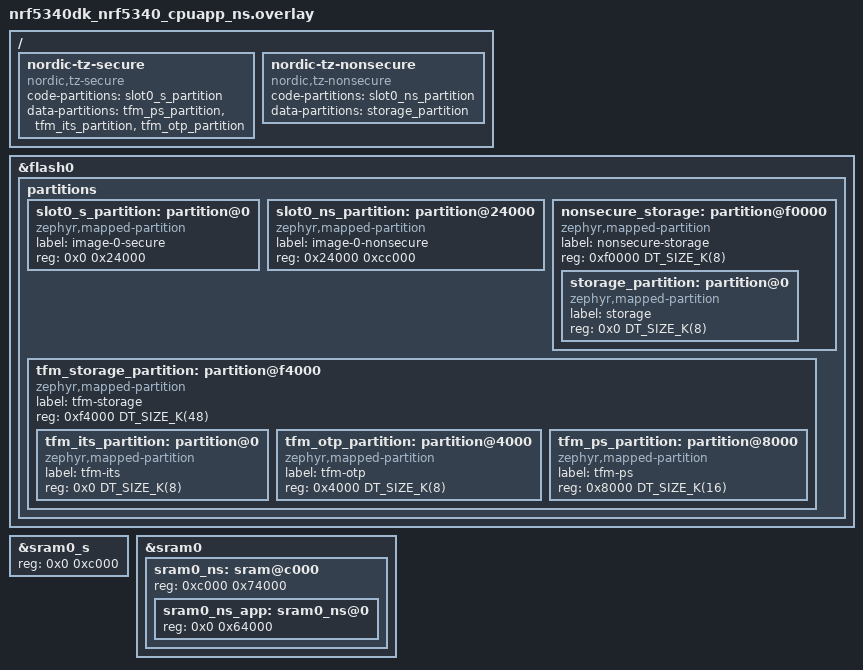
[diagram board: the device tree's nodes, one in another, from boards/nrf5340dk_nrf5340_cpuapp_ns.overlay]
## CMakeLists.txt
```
#
# Copyright (c) 2024 Nordic Semiconductor ASA
#
# SPDX-License-Identifier: LicenseRef-Nordic-5-Clause
#

cmake_minimum_required(VERSION 3.20.0)

find_package(Zephyr REQUIRED HINTS $ENV{ZEPHYR_BASE})
project(softap_wifi_provision_sample)

target_sources(app PRIVATE src/main.c)
```

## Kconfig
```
#
# Copyright (c) 2024 Nordic Semiconductor ASA
#
# SPDX-License-Identifier: LicenseRef-Nordic-5-Clause
#

menu "SoftAP Wi-Fi provision sample"

config SOFTAP_WIFI_PROVISION_SAMPLE_PSM_DISABLED_SECONDS
	int "Wi-Fi PSM disabled seconds"
	default 120
	help
	  Time in seconds that Wi-Fi power saving mode is disabled after completed provisioning.
	  Disabling Power Save Mode is needed to make the device discoverable reliably via
	  mDNS post provisioning.
	  Service Discovery has proven to be unstable in PSM.

menu "Zephyr Kernel"
source "Kconfig.zephyr"
endmenu

module = SOFTAP_WIFI_PROVISION_SAMPLE
module-str = SoftAP Wi-Fi provision sample
source "$(ZEPHYR_BASE)/subsys/logging/Kconfig.template.log_config"

endmenu
```

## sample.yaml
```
sample:
  name: SoftAP Wi-Fi Provision sample
tests:
  sample.softap.wifi.provision:
    sysbuild: true
    build_only: true
    platform_allow: nrf7002dk/nrf5340/cpuapp/ns
    integration_platforms:
      - nrf7002dk/nrf5340/cpuapp/ns
    tags:
      - ci_build
      - sysbuild
      - ci_samples_wifi
  sample.nrf7002_eks.softap.wifi.provision:
    sysbuild: true
    build_only: true
    extra_args:
      - softap_SHIELD=nrf7002ek
    integration_platforms:
      - nrf5340dk/nrf5340/cpuapp/ns
    platform_allow:
      - nrf5340dk/nrf5340/cpuapp/ns
    tags:
      - ci_build
      - sysbuild
      - ci_samples_wifi
  sample.nrf54l15.softap.wifi.provision:
    sysbuild: true
    build_only: true
    extra_args:
      - softap_SHIELD="nrf7002eb_interposer_p1;nrf7002eb"
      - softap_SNIPPET=nrf70-wifi
      - CONFIG_HEAP_MEM_POOL_IGNORE_MIN=n
    integration_platforms:
      - nrf54l15dk/nrf54l15/cpuapp
    platform_allow:
      - nrf54l15dk/nrf54l15/cpuapp
    tags:
      - ci_build
      - sysbuild
      - ci_samples_wifi
  sample.nrf54h20.nrf7002eb_interposer_p1.softap.wifi.provision:
    sysbuild: true
    build_only: true
    extra_args:
      - softap_SHIELD="nrf7002eb_interposer_p1;nrf7002eb"
      - softap_SNIPPET=nrf70-wifi
      - CONFIG_MBEDTLS_SSL_SERVER_NAME_INDICATION=n
    integration_platforms:
      - nrf54h20dk/nrf54h20/cpuapp
    platform_allow:
      - nrf54h20dk/nrf54h20/cpuapp
    tags:
      - ci_build
      - sysbuild
      - ci_samples_wifi
  sample.54lm20dk.nrf7002eb2.softap.wifi.provision:
    sysbuild: true
    build_only: true
    extra_args:
      - softap_SHIELD="nrf7002eb2"
    integration_platforms:
      - nrf54lm20dk/nrf54lm20a/cpuapp
      - nrf54lm20dk/nrf54lm20b/cpuapp
    platform_allow:
      - nrf54lm20dk/nrf54lm20a/cpuapp
      - nrf54lm20dk/nrf54lm20b/cpuapp
    tags:
      - ci_build
      - sysbuild
      - ci_samples_wifi
  sample.nrf7120.softap.wifi.provision:
    sysbuild: true
    build_only: true
    integration_platforms:
      - nrf7120dk/nrf7120/cpuapp/ns
    platform_allow:
      - nrf7120dk/nrf7120/cpuapp/ns
      - nrf7120dk/nrf7120e/cpuapp/ns
    tags:
      - ci_build
      - sysbuild
      - ci_samples_nrf71_wifi
```

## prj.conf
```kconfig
#
# Copyright (c) 2024 Nordic Semiconductor ASA
#
# SPDX-License-Identifier: LicenseRef-Nordic-5-Clause
#

# Optimize TF-M
CONFIG_TFM_PROFILE_TYPE_SMALL=y

# Optimize Wi-Fi stack to save some memory.
CONFIG_NRF_WIFI_DATA_HEAP_SIZE=53000

# Wi-Fi
CONFIG_WIFI=y
CONFIG_WIFI_NM_WPA_SUPPLICANT=y
CONFIG_WIFI_NM_WPA_SUPPLICANT_AP=y
CONFIG_NET_L2_ETHERNET=y
CONFIG_WIFI_CREDENTIALS=y
CONFIG_SETTINGS=y

# General
CONFIG_LOG=y
CONFIG_LOG_MODE_IMMEDIATE=y
CONFIG_ASSERT=y
CONFIG_ASSERT_VERBOSE=n
CONFIG_REBOOT=y

# Link-time optimizations
CONFIG_LTO=y
CONFIG_ISR_TABLES_LOCAL_DECLARATION=y

# Temporarily enable FS support so that linking succeeds.
CONFIG_FILE_SYSTEM=y
CONFIG_MAIN_STACK_SIZE=6704
CONFIG_NANOPB=y
CONFIG_SMF=y

# Scan Results
CONFIG_SOFTAP_WIFI_PROVISION_SAMPLE_SCAN_RESULTS=20

# HTTP parser
CONFIG_HTTP_PARSER=y
CONFIG_HTTP_PARSER_URL=y

# DK Butons and LEDs
CONFIG_DK_LIBRARY=y

# Networking config
CONFIG_NETWORKING=y
CONFIG_NET_CONNECTION_MANAGER=y
CONFIG_NET_IPV4=y
# Disable IPv6 to save memory
CONFIG_NET_IPV6=n
CONFIG_NET_TCP=y
CONFIG_NET_UDP=y
CONFIG_NET_SOCKETS=y
CONFIG_NET_MAX_CONN=8
CONFIG_NET_SOCKETS_TLS_MAX_CONTEXTS=2
CONFIG_NET_SOCKETS_SOCKOPT_TLS=y

# Zephyr NET Connection Manager connectivity layer
CONFIG_L2_WIFI_CONNECTIVITY=y
CONFIG_L2_WIFI_CONNECTIVITY_AUTO_CONNECT=n
CONFIG_L2_WIFI_CONNECTIVITY_AUTO_DOWN=n

# SoftAP Wi-Fi Provision library
CONFIG_SOFTAP_WIFI_PROVISION=y
CONFIG_SOFTAP_WIFI_PROVISION_THREAD_STACK_SIZE=8192
# Disable socket close on completed provisioning to keep mDNS SD running.
# SD depends on the socket being open for a specified port.
CONFIG_SOFTAP_WIFI_PROVISION_SOCKET_CLOSE_ON_COMPLETION=n
CONFIG_SOFTAP_WIFI_PROVISION_LOG_LEVEL_DBG=y
CONFIG_WIFI_NM_WPA_SUPPLICANT_THREAD_STACK_SIZE=8192

# (M)DNS
CONFIG_MDNS_RESPONDER=y
CONFIG_DNS_SD=y
CONFIG_MDNS_RESPONDER_DNS_SD=y
CONFIG_NET_HOSTNAME_ENABLE=y
CONFIG_NET_HOSTNAME="wifiprov"
# Disable POSIX uname support to suppress build warning that hostname is too long.
CONFIG_POSIX_SINGLE_PROCESS=n

# DHCPv4 client and server
CONFIG_NET_DHCPV4=y
CONFIG_NET_DHCPV4_SERVER=y

# Store TLS credentials to protected storage.
CONFIG_TLS_CREDENTIALS=y
CONFIG_TLS_CREDENTIALS_BACKEND_PROTECTED_STORAGE=y

CONFIG_FLASH=y
CONFIG_FLASH_PAGE_LAYOUT=y
CONFIG_FLASH_MAP=y
CONFIG_ZMS=y
CONFIG_SETTINGS=y
CONFIG_SETTINGS_ZMS=y

# Disable auto init of NET config as the softAP Wi-Fi provision library will manually set its
# own IP configuration.
CONFIG_NET_CONFIG_AUTO_INIT=n

# Default mbedTLS heap is 512 B; PEM decode of server cert/key needs more or load fails with
# MBEDTLS_ERR_PEM_ALLOC_FAILED (-0x1180) during tls_credential_add().
CONFIG_MBEDTLS_HEAP_SIZE=49152

# nrf_security can leave PEM parsing off; embedded PEM certs need this or x509 parse fails with
# MBEDTLS_ERR_X509_INVALID_FORMAT (-0x2180).
CONFIG_MBEDTLS_PEM_PARSE_C=y

# Embedded PEMs are ECDSA P-256 (prime256v1). PSA must list
# secp256r1 and ECDSA/ECDH or mbedtls_x509_crt_parse() returns MBEDTLS_ERR_X509_INVALID_FORMAT
# (-0x2180). TLS server ECDHE uses psa_generate_key() then psa_export_public_key() for the
# ephemeral key; without PSA_WANT_KEY_TYPE_ECC_KEY_PAIR_GENERATE / EXPORT, those calls map to
# MBEDTLS_ERR_SSL_FEATURE_UNAVAILABLE (-0x7080). See samples/crypto/psa_tls/prj.conf.
CONFIG_PSA_WANT_ALG_ECDSA=y
CONFIG_PSA_WANT_ALG_ECDH=y
CONFIG_PSA_WANT_ECC_SECP_R1_256=y
CONFIG_PSA_WANT_KEY_TYPE_ECC_PUBLIC_KEY=y
CONFIG_PSA_WANT_KEY_TYPE_ECC_KEY_PAIR_IMPORT=y
CONFIG_PSA_WANT_KEY_TYPE_ECC_KEY_PAIR_GENERATE=y
CONFIG_PSA_WANT_KEY_TYPE_ECC_KEY_PAIR_EXPORT=y
```

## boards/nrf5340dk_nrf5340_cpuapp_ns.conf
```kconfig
#
# Copyright (c) 2026 Nordic Semiconductor ASA
#
# SPDX-License-Identifier: LicenseRef-Nordic-5-Clause
#

# Store Wi-Fi credentials using PSA storage
CONFIG_TFM_PROFILE_TYPE_SMALL=y
CONFIG_MBEDTLS_PSA_CRYPTO_C=y

# Some size optimizations to accommodate non-secure builds.
CONFIG_NET_STATISTICS=n
CONFIG_NET_STATISTICS_WIFI=n
CONFIG_NET_STATISTICS_USER_API=n
CONFIG_NET_PKT_RX_COUNT=8
CONFIG_NET_PKT_TX_COUNT=4
CONFIG_NET_BUF_RX_COUNT=8
CONFIG_NET_BUF_TX_COUNT=8
CONFIG_NET_TC_TX_COUNT=1
CONFIG_NET_TX_STACK_SIZE=2048
CONFIG_NET_RX_STACK_SIZE=2048
```

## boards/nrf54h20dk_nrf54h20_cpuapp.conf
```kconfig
CONFIG_WIFI_CREDENTIALS=y
# Needed for Wi-Fi credentials
CONFIG_FLASH=y
CONFIG_FLASH_PAGE_LAYOUT=y
CONFIG_FLASH_MAP=y
CONFIG_ZMS=y
CONFIG_SETTINGS=y
```

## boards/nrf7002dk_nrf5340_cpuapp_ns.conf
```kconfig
#
# Copyright (c) 2026 Nordic Semiconductor ASA
#
# SPDX-License-Identifier: LicenseRef-Nordic-5-Clause
#

# Store Wi-Fi credentials using PSA storage
CONFIG_TFM_PROFILE_TYPE_SMALL=y
CONFIG_MBEDTLS_PSA_CRYPTO_C=y

# Some size optimizations to accommodate non-secure builds.
CONFIG_NET_STATISTICS=n
CONFIG_NET_STATISTICS_WIFI=n
CONFIG_NET_STATISTICS_USER_API=n
CONFIG_NET_PKT_RX_COUNT=8
CONFIG_NET_PKT_TX_COUNT=4
CONFIG_NET_BUF_RX_COUNT=8
CONFIG_NET_BUF_TX_COUNT=8
CONFIG_NET_TC_TX_COUNT=1
CONFIG_NET_TX_STACK_SIZE=2048
CONFIG_NET_RX_STACK_SIZE=2048

#NRF70 specific configuration
CONFIG_WIFI_NRF70=y
CONFIG_NRF70_AP_MODE=y
CONFIG_NRF_WIFI_DATA_HEAP_SIZE=53000
```

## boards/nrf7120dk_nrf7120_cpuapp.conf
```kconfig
#
# Copyright (c) 2026 Nordic Semiconductor
#
# SPDX-License-Identifier: LicenseRef-Nordic-5-Clause
#

CONFIG_WIFI_NRF71=y
CONFIG_NRF71_AP_MODE=y
CONFIG_NRF71_RX_NUM_BUFS=16
CONFIG_NRF71_MAX_TX_AGGREGATION=4
CONFIG_NRF_WIFI_DATA_HEAP_SIZE=90000
```

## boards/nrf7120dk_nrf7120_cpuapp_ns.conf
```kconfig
#
# Copyright (c) 2026 Nordic Semiconductor
#
# SPDX-License-Identifier: LicenseRef-Nordic-5-Clause
#

CONFIG_WIFI_NRF71=y
CONFIG_NRF71_WIFI_AP_SUPPORT=y
CONFIG_NRF71_WIFI_RX_NUM_BUFS=16
CONFIG_NRF71_WIFI_MAX_TX_AGGREGATION=4
CONFIG_NRF71_WIFI_DATA_HEAP_SIZE=90000

# nRF7120 (SOC_SERIES_NRF71) defaults TFM_ITS_ENCRYPTED=y, which conflicts with
# PSA_FRAMEWORK_HAS_MM_IOVEC (enabled via TFM_PROFILE_TYPE_SMALL in prj.conf).
# TLS credentials use PS (Protected Storage), not ITS, so disabling ITS encryption
# is safe here.
CONFIG_TFM_ITS_ENCRYPTED=n

CONFIG_DK_LIBRARY=n
```

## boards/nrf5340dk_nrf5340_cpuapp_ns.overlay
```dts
/*
 * Copyright (c) 2026 Nordic Semiconductor ASA
 *
 * SPDX-License-Identifier: LicenseRef-Nordic-5-Clause
 */

/*
 * Flash partition layout for nRF5340DK (nRF5340 cpuapp/ns) without MCUboot.
 * PM is disabled; TF-M is the only S-mode component.
 *
 *   slot0_s_partition  @ 0x000000  144 KB  TF-M secure image
 *   slot0_ns_partition @ 0x024000  816 KB  NS application image
 *   nonsecure_storage  @ 0x0f0000    8 KB  Settings (NS-accessible)
 *   tfm_storage        @ 0x0f4000   48 KB  TF-M ITS + OTP + PS
 */

/delete-node/ &boot_partition;
/delete-node/ &slot0_partition;
/delete-node/ &slot1_partition;
/delete-node/ &tfm_its_partition;
/delete-node/ &tfm_otp_partition;
/delete-node/ &tfm_ps_partition;
/delete-node/ &storage_partition;
/delete-node/ &sram0_ns;

&flash0 {
	partitions {
		slot0_s_partition: partition@0 {
			compatible = "zephyr,mapped-partition";
			label = "image-0-secure";
			reg = <0x0 0x24000>;
		};

		slot0_ns_partition: partition@24000 {
			compatible = "zephyr,mapped-partition";
			label = "image-0-nonsecure";
			reg = <0x24000 0xcc000>;
		};

		nonsecure_storage: partition@f0000 {
			compatible = "zephyr,mapped-partition";
			label = "nonsecure-storage";
			reg = <0xf0000 DT_SIZE_K(8)>;
			ranges = <0x0 0xf0000 DT_SIZE_K(8)>;
			#address-cells = <1>;
			#size-cells = <1>;

			storage_partition: partition@0 {
				compatible = "zephyr,mapped-partition";
				label = "storage";
				reg = <0x0 DT_SIZE_K(8)>;
			};
		};

		tfm_storage_partition: partition@f4000 {
			compatible = "zephyr,mapped-partition";
			label = "tfm-storage";
			reg = <0xf4000 DT_SIZE_K(48)>;
			ranges = <0x0 0xf4000 DT_SIZE_K(48)>;
			#address-cells = <1>;
			#size-cells = <1>;

			tfm_its_partition: partition@0 {
				compatible = "zephyr,mapped-partition";
				label = "tfm-its";
				reg = <0x0 DT_SIZE_K(8)>;
			};

			tfm_otp_partition: partition@4000 {
				compatible = "zephyr,mapped-partition";
				label = "tfm-otp";
				reg = <0x4000 DT_SIZE_K(8)>;
			};

			tfm_ps_partition: partition@8000 {
				compatible = "zephyr,mapped-partition";
				label = "tfm-ps";
				reg = <0x8000 DT_SIZE_K(16)>;
			};
		};
	};
};

/*
 * SRAM split: TF-M secure uses 48 KiB at base; NS app gets the rest.
 */
&sram0_s {
	reg = <0x0 0xc000>;
};

&sram0 {
	sram0_ns: sram@c000 {
		#address-cells = <1>;
		#size-cells = <1>;
		reg = <0xc000 0x74000>;
		ranges = <0x0 0xc000 0x74000>;

		sram0_ns_app: sram0_ns@0 {
			reg = <0x0 0x64000>;
		};
	};
};

/ {
	/delete-node/ nordic-tz-secure;
	/delete-node/ nordic-tz-nonsecure;

	nordic-tz-secure {
		compatible = "nordic,tz-secure";
		code-partitions = <&slot0_s_partition>;
		data-partitions = <&tfm_ps_partition>,
				  <&tfm_its_partition>,
				  <&tfm_otp_partition>;
	};

	nordic-tz-nonsecure {
		compatible = "nordic,tz-nonsecure";
		code-partitions = <&slot0_ns_partition>;
		data-partitions = <&storage_partition>;
	};
};
```

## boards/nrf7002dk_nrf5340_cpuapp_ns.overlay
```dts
/*
 * Copyright (c) 2026 Nordic Semiconductor ASA
 *
 * SPDX-License-Identifier: LicenseRef-Nordic-5-Clause
 */

/*
 * Flash partition layout for nRF7002DK (nRF5340 cpuapp/ns) without MCUboot.
 * PM is disabled; TF-M is the only S-mode component.
 *
 *   slot0_s_partition  @ 0x000000  144 KB  TF-M secure image
 *   slot0_ns_partition @ 0x024000  816 KB  NS application image
 *   nonsecure_storage  @ 0x0f0000    8 KB  Settings (NS-accessible)
 *   tfm_storage        @ 0x0f4000   48 KB  TF-M ITS + OTP + PS
 */

/delete-node/ &boot_partition;
/delete-node/ &slot0_partition;
/delete-node/ &slot1_partition;
/delete-node/ &tfm_its_partition;
/delete-node/ &tfm_otp_partition;
/delete-node/ &tfm_ps_partition;
/delete-node/ &storage_partition;
/delete-node/ &sram0_ns;

&flash0 {
	partitions {
		slot0_s_partition: partition@0 {
			compatible = "zephyr,mapped-partition";
			label = "image-0-secure";
			reg = <0x0 0x24000>;
		};

		slot0_ns_partition: partition@24000 {
			compatible = "zephyr,mapped-partition";
			label = "image-0-nonsecure";
			reg = <0x24000 0xcc000>;
		};

		nonsecure_storage: partition@f0000 {
			compatible = "zephyr,mapped-partition";
			label = "nonsecure-storage";
			reg = <0xf0000 DT_SIZE_K(8)>;
			ranges = <0x0 0xf0000 DT_SIZE_K(8)>;
			#address-cells = <1>;
			#size-cells = <1>;

			storage_partition: partition@0 {
				compatible = "zephyr,mapped-partition";
				label = "storage";
				reg = <0x0 DT_SIZE_K(8)>;
			};
		};

		tfm_storage_partition: partition@f4000 {
			compatible = "zephyr,mapped-partition";
			label = "tfm-storage";
			reg = <0xf4000 DT_SIZE_K(48)>;
			ranges = <0x0 0xf4000 DT_SIZE_K(48)>;
			#address-cells = <1>;
			#size-cells = <1>;

			tfm_its_partition: partition@0 {
				compatible = "zephyr,mapped-partition";
				label = "tfm-its";
				reg = <0x0 DT_SIZE_K(8)>;
			};

			tfm_otp_partition: partition@4000 {
				compatible = "zephyr,mapped-partition";
				label = "tfm-otp";
				reg = <0x4000 DT_SIZE_K(8)>;
			};

			tfm_ps_partition: partition@8000 {
				compatible = "zephyr,mapped-partition";
				label = "tfm-ps";
				reg = <0x8000 DT_SIZE_K(16)>;
			};
		};
	};
};

/*
 * SRAM split: TF-M secure uses 48 KiB at base; NS app gets the rest.
 */
&sram0_s {
	reg = <0x0 0xc000>;
};

&sram0 {
	sram0_ns: sram@c000 {
		#address-cells = <1>;
		#size-cells = <1>;
		reg = <0xc000 0x74000>;
		ranges = <0x0 0xc000 0x74000>;

		sram0_ns_app: sram0_ns@0 {
			reg = <0x0 0x64000>;
		};
	};
};

/ {
	/delete-node/ nordic-tz-secure;
	/delete-node/ nordic-tz-nonsecure;

	nordic-tz-secure {
		compatible = "nordic,tz-secure";
		code-partitions = <&slot0_s_partition>;
		data-partitions = <&tfm_ps_partition>,
				  <&tfm_its_partition>,
				  <&tfm_otp_partition>;
	};

	nordic-tz-nonsecure {
		compatible = "nordic,tz-nonsecure";
		code-partitions = <&slot0_ns_partition>;
		data-partitions = <&storage_partition>;
	};
};
```

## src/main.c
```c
/*
 * Copyright (c) 2024 Nordic Semiconductor ASA
 *
 * SPDX-License-Identifier: LicenseRef-Nordic-5-Clause
 */

#include <stdio.h>
#include <errno.h>
#include <zephyr/kernel.h>
#include <zephyr/logging/log.h>
#include <zephyr/logging/log_ctrl.h>
#include <zephyr/sys/reboot.h>
#include <zephyr/net/wifi_mgmt.h>
#include <zephyr/net/net_mgmt.h>
#include <zephyr/net/net_event.h>
#include <zephyr/net/conn_mgr_monitor.h>
#include <zephyr/net/conn_mgr_connectivity.h>
#include <zephyr/net/dhcpv4.h>
#include <dk_buttons_and_leds.h>
#include <net/softap_wifi_provision.h>

LOG_MODULE_REGISTER(softap_wifi_provision_sample, CONFIG_SOFTAP_WIFI_PROVISION_SAMPLE_LOG_LEVEL);

/* Macro used to subscribe to specific Zephyr NET management events. */
#define L4_EVENT_MASK (NET_EVENT_L4_CONNECTED | NET_EVENT_L4_DISCONNECTED)
#define CONN_LAYER_EVENT_MASK (NET_EVENT_CONN_IF_FATAL_ERROR)

/* Macro called upon a fatal error, reboots the device. */
#define FATAL_ERROR()								\
	LOG_ERR("Fatal error!%s", IS_ENABLED(CONFIG_RESET_ON_FATAL_ERROR) ?	\
				  " Rebooting the device" : "");		\
	LOG_PANIC();								\
	IF_ENABLED(CONFIG_REBOOT, (sys_reboot(0)))

/* Callbacks for Zephyr NET management events. */
static struct net_mgmt_event_callback l4_cb;
static struct net_mgmt_event_callback conn_cb;

static void l4_event_handler(struct net_mgmt_event_callback *cb,
			     uint64_t event,
			     struct net_if *iface)
{
	switch (event) {
	case NET_EVENT_L4_CONNECTED:
		LOG_INF("Network connected");

#ifdef CONFIG_DK_LIBRARY
		int ret = dk_set_led_on(DK_LED2);

		if (ret) {
			LOG_ERR("dk_set_led_on, error: %d", ret);
			FATAL_ERROR();
			return;
		}
#endif /* CONFIG_DK_LIBRARY */

		/* Start the DHCPv4 client after the device is provisioned to a network.
		 * This is needed to get a dynamic IPv4 address from the APs DHCPv4 server.
		 */
		net_dhcpv4_start(iface);
		break;
	case NET_EVENT_L4_DISCONNECTED:
		LOG_INF("Network disconnected");
		break;
	default:
		/* Don't care */
		return;
	}
}

static void connectivity_event_handler(struct net_mgmt_event_callback *cb,
				       uint64_t event,
				       struct net_if *iface)
{
	if (event == NET_EVENT_CONN_IF_FATAL_ERROR) {
		LOG_ERR("NET_EVENT_CONN_IF_FATAL_ERROR");
		FATAL_ERROR();
		return;
	}
}

/* Callback for softAP Wi-Fi provision library events. */
static void softap_wifi_provision_handler(const struct softap_wifi_provision_evt *evt)
{
	switch (evt->type) {
	case SOFTAP_WIFI_PROVISION_EVT_STARTED:
		LOG_INF("Provisioning started");
#ifdef CONFIG_DK_LIBRARY
		int ret;

		ret = dk_set_led_on(DK_LED1);
		if (ret) {
			LOG_ERR("dk_set_led_on, error: %d", ret);
			FATAL_ERROR();
			return;
		}
#endif /* CONFIG_DK_LIBRARY */

		break;
	case SOFTAP_WIFI_PROVISION_EVT_CLIENT_CONNECTED:
		LOG_INF("Client connected");
		break;
	case SOFTAP_WIFI_PROVISION_EVT_CLIENT_DISCONNECTED:
		LOG_INF("Client disconnected");
		break;
	case SOFTAP_WIFI_PROVISION_EVT_CREDENTIALS_RECEIVED:
		LOG_INF("Wi-Fi credentials received");
		break;
	case SOFTAP_WIFI_PROVISION_EVT_COMPLETED:
		LOG_INF("Provisioning completed");
		break;
	case SOFTAP_WIFI_PROVISION_EVT_UNPROVISIONED_REBOOT_NEEDED:
		LOG_INF("Reboot request notified, rebooting...");

		LOG_PANIC();
		IF_ENABLED(CONFIG_REBOOT, (sys_reboot(0)));
		break;
	case SOFTAP_WIFI_PROVISION_EVT_FATAL_ERROR:
		LOG_ERR("Provisioning failed, fatal error!");
		FATAL_ERROR();
		break;
	default:
		/* Don't care */
		return;
	}
}

#ifdef CONFIG_DK_LIBRARY
static void button_handler(uint32_t button_states, uint32_t has_changed)
{
	if ((has_changed & DK_BTN1_MSK) && (button_states & DK_BTN1_MSK)) {
		LOG_INF("Button 1 pressed");

		int ret = softap_wifi_provision_reset();

		if (ret) {
			LOG_ERR("softap_wifi_provision_reset, error: %d", ret);
			FATAL_ERROR();
			return;
		}
	}
}
#endif /* CONFIG_DK_LIBRARY */

static int wifi_power_saving_disable(void)
{
	int ret;
	struct net_if *iface = net_if_get_first_wifi();
		struct wifi_ps_params params = {
		.enabled = WIFI_PS_DISABLED
	};

	ret = net_mgmt(NET_REQUEST_WIFI_PS, iface, &params, sizeof(params));
	if (ret) {
		LOG_ERR("Failed to disable PSM, error: %d", ret);
		FATAL_ERROR();
		return ret;
	}

	return 0;
}

static int wifi_power_saving_enable(void)
{
	int ret;
	struct net_if *iface = net_if_get_first_wifi();
	struct wifi_ps_params params = {
		.enabled = WIFI_PS_ENABLED
	};

	ret = net_mgmt(NET_REQUEST_WIFI_PS, iface, &params, sizeof(params));
	if (ret) {
		LOG_ERR("Failed to enable PSM, error: %d", ret);
		FATAL_ERROR();
		return ret;
	}

	return 0;
}

/* Function used to disable and re-enable PSM after a configured amount of time post provisioning.
 * This is to ensure that the device is discoverable via mDNS so that clients can
 * confirm that provisioning succeeded. This is needed due to mDNS SD being unstable
 * in Power Save Mode.
 */
static void psm_set(void)
{
	int ret;

	ret = wifi_power_saving_disable();
	if (ret) {
		LOG_ERR("wifi_power_saving_disable, error: %d", ret);
		FATAL_ERROR();
		return;
	}

	LOG_INF("PSM disabled");

	k_sleep(K_SECONDS(CONFIG_SOFTAP_WIFI_PROVISION_SAMPLE_PSM_DISABLED_SECONDS));

	ret = wifi_power_saving_enable();
	if (ret) {
		LOG_ERR("wifi_power_saving_enable, error: %d", ret);
		FATAL_ERROR();
		return;
	}

	LOG_INF("PSM enabled");
}

int main(void)
{
	int ret;
	bool provisioning_completed = false;

	LOG_INF("SoftAP Wi-Fi provision sample started");

#ifdef CONFIG_DK_LIBRARY
	ret = dk_buttons_init(button_handler);
	if (ret) {
		LOG_ERR("dk_buttons_init, error: %d", ret);
		FATAL_ERROR();
		return ret;
	}

	ret = dk_leds_init();
	if (ret) {
		LOG_ERR("dk_leds_init, error: %d", ret);
		FATAL_ERROR();
		return ret;
	}
#endif /* CONFIG_DK_LIBRARY */

	ret = softap_wifi_provision_init(softap_wifi_provision_handler);
	if (ret) {
		LOG_ERR("softap_wifi_provision_init, error: %d", ret);
		FATAL_ERROR();
		return ret;
	}

	ret = conn_mgr_all_if_up(true);
	if (ret) {
		LOG_ERR("conn_mgr_all_if_up, error: %d", ret);
		FATAL_ERROR();
		return ret;
	}

	LOG_INF("Network interface brought up");

	ret = softap_wifi_provision_start();
	switch (ret) {
	case 0:
		provisioning_completed = true;
		break;
	case -EALREADY:
		LOG_INF("Wi-Fi credentials found, skipping provisioning");
		break;
	default:
		LOG_ERR("softap_wifi_provision_start, error: %d", ret);
		FATAL_ERROR();
		return ret;
	}

	/* Register NET mgmt handlers for Connection Manager events after provisioning
	 * is completed. This is to avoid receiving events during provisioning when the device is
	 * in softAP (server) mode and gets assigned an IP,
	 * which triggers the NET_EVENT_L4_CONNECTED.
	 */

	/* Setup handler for Zephyr NET Connection Manager events. */
	net_mgmt_init_event_callback(&l4_cb, l4_event_handler, L4_EVENT_MASK);
	net_mgmt_add_event_callback(&l4_cb);

	/* Setup handler for Zephyr NET Connection Manager Connectivity layer. */
	net_mgmt_init_event_callback(&conn_cb, connectivity_event_handler, CONN_LAYER_EVENT_MASK);
	net_mgmt_add_event_callback(&conn_cb);

	ret = conn_mgr_all_if_connect(true);
	if (ret) {
		LOG_ERR("conn_mgr_all_if_connect, error: %d", ret);
		FATAL_ERROR();
		return ret;
	}

	if (provisioning_completed) {
		psm_set();
	}

	return 0;
}
```
